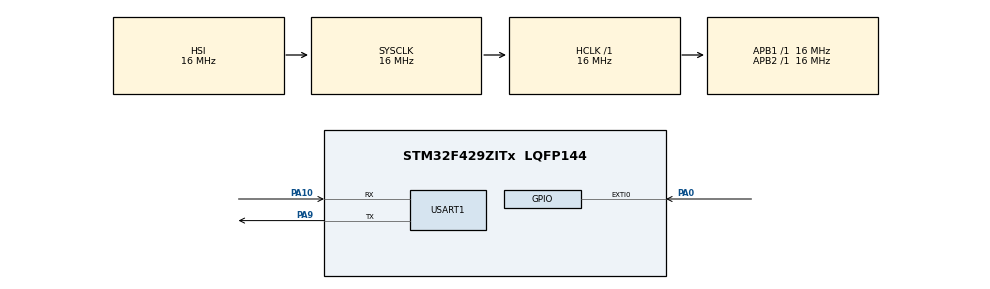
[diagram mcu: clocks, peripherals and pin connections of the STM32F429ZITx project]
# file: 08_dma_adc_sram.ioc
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ADC1.Channel-0\#ChannelRegularConversion=ADC_CHANNEL_TEMPSENSOR
ADC1.Channel-1\#ChannelRegularConversion=ADC_CHANNEL_TEMPSENSOR
ADC1.Channel-10\#ChannelRegularConversion=ADC_CHANNEL_TEMPSENSOR
ADC1.Channel-11\#ChannelRegularConversion=ADC_CHANNEL_TEMPSENSOR
ADC1.Channel-12\#ChannelRegularConversion=ADC_CHANNEL_TEMPSENSOR
ADC1.Channel-13\#ChannelRegularConversion=ADC_CHANNEL_TEMPSENSOR
ADC1.Channel-14\#ChannelRegularConversion=ADC_CHANNEL_TEMPSENSOR
ADC1.Channel-15\#ChannelRegularConversion=ADC_CHANNEL_TEMPSENSOR
ADC1.Channel-2\#ChannelRegularConversion=ADC_CHANNEL_TEMPSENSOR
ADC1.Channel-3\#ChannelRegularConversion=ADC_CHANNEL_TEMPSENSOR
ADC1.Channel-4\#ChannelRegularConversion=ADC_CHANNEL_TEMPSENSOR
ADC1.Channel-5\#ChannelRegularConversion=ADC_CHANNEL_TEMPSENSOR
ADC1.Channel-6\#ChannelRegularConversion=ADC_CHANNEL_TEMPSENSOR
ADC1.Channel-7\#ChannelRegularConversion=ADC_CHANNEL_TEMPSENSOR
ADC1.Channel-8\#ChannelRegularConversion=ADC_CHANNEL_TEMPSENSOR
ADC1.Channel-9\#ChannelRegularConversion=ADC_CHANNEL_TEMPSENSOR
ADC1.ClockPrescaler=ADC_CLOCK_SYNC_PCLK_DIV2
ADC1.ContinuousConvMode=ENABLE
ADC1.DMAContinuousRequests=DISABLE
ADC1.DataAlign=ADC_DATAALIGN_RIGHT
ADC1.DiscontinuousConvMode=DISABLE
ADC1.EOCSelection=ADC_EOC_SINGLE_CONV
ADC1.EnableAnalogWatchDog=false
ADC1.ExternalTrigConv=ADC_SOFTWARE_START
ADC1.ExternalTrigConvEdge=ADC_EXTERNALTRIGCONVEDGE_NONE
ADC1.InjNumberOfConversion=0
ADC1.NbrOfConversion=16
ADC1.NbrOfConversionFlag=1
ADC1.Rank-0\#ChannelRegularConversion=1
ADC1.Rank-1\#ChannelRegularConversion=2
ADC1.Rank-10\#ChannelRegularConversion=11
ADC1.Rank-11\#ChannelRegularConversion=12
ADC1.Rank-12\#ChannelRegularConversion=13
ADC1.Rank-13\#ChannelRegularConversion=14
ADC1.Rank-14\#ChannelRegularConversion=15
ADC1.Rank-15\#ChannelRegularConversion=16
ADC1.Rank-2\#ChannelRegularConversion=3
ADC1.Rank-3\#ChannelRegularConversion=4
ADC1.Rank-4\#ChannelRegularConversion=5
ADC1.Rank-5\#ChannelRegularConversion=6
ADC1.Rank-6\#ChannelRegularConversion=7
ADC1.Rank-7\#ChannelRegularConversion=8
ADC1.Rank-8\#ChannelRegularConversion=9
ADC1.Rank-9\#ChannelRegularConversion=10
ADC1.Resolution=ADC_RESOLUTION_12B
ADC1.SamplingTime-0\#ChannelRegularConversion=ADC_SAMPLETIME_3CYCLES
ADC1.SamplingTime-1\#ChannelRegularConversion=ADC_SAMPLETIME_3CYCLES
ADC1.SamplingTime-10\#ChannelRegularConversion=ADC_SAMPLETIME_3CYCLES
ADC1.SamplingTime-11\#ChannelRegularConversion=ADC_SAMPLETIME_3CYCLES
ADC1.SamplingTime-12\#ChannelRegularConversion=ADC_SAMPLETIME_3CYCLES
ADC1.SamplingTime-13\#ChannelRegularConversion=ADC_SAMPLETIME_3CYCLES
ADC1.SamplingTime-14\#ChannelRegularConversion=ADC_SAMPLETIME_3CYCLES
ADC1.SamplingTime-15\#ChannelRegularConversion=ADC_SAMPLETIME_3CYCLES
ADC1.SamplingTime-2\#ChannelRegularConversion=ADC_SAMPLETIME_3CYCLES
ADC1.SamplingTime-3\#ChannelRegularConversion=ADC_SAMPLETIME_3CYCLES
ADC1.SamplingTime-4\#ChannelRegularConversion=ADC_SAMPLETIME_3CYCLES
ADC1.SamplingTime-5\#ChannelRegularConversion=ADC_SAMPLETIME_3CYCLES
ADC1.SamplingTime-6\#ChannelRegularConversion=ADC_SAMPLETIME_3CYCLES
ADC1.SamplingTime-7\#ChannelRegularConversion=ADC_SAMPLETIME_3CYCLES
ADC1.SamplingTime-8\#ChannelRegularConversion=ADC_SAMPLETIME_3CYCLES
ADC1.SamplingTime-9\#ChannelRegularConversion=ADC_SAMPLETIME_3CYCLES
ADC1.ScanConvMode=ENABLE
ADC1.master=1
Dma.ADC1.0.Direction=DMA_PERIPH_TO_MEMORY
Dma.ADC1.0.FIFOMode=DMA_FIFOMODE_DISABLE
Dma.ADC1.0.Instance=DMA2_Stream0
Dma.ADC1.0.MemDataAlignment=DMA_MDATAALIGN_HALFWORD
Dma.ADC1.0.MemInc=DMA_MINC_ENABLE
Dma.ADC1.0.Mode=DMA_NORMAL
Dma.ADC1.0.PeriphDataAlignment=DMA_PDATAALIGN_HALFWORD
Dma.ADC1.0.PeriphInc=DMA_PINC_DISABLE
Dma.ADC1.0.Priority=DMA_PRIORITY_LOW
Dma.Request0=ADC1
Mcu.Family=STM32F4
Mcu.Name=STM32F429ZITx
Mcu.Package=LQFP144
NVIC.DMA2_Stream0_IRQn=true\:0\:0\:false\:false\:true\:false
NVIC.EXTI0_IRQn=true\:0\:0\:false\:false\:true\:true
NVIC.PriorityGroup=NVIC_PRIORITYGROUP_4
PA0/WKUP.Signal=GPXTI0
PA10.Mode=Asynchronous
PA10.Signal=USART1_RX
PA9.Mode=Asynchronous
PA9.Signal=USART1_TX
ProjectManager.HeapSize=0x200
ProjectManager.StackSize=0x400
ProjectManager.TargetToolchain=SW4STM32
RCC.AHBFreq_Value=16000000
RCC.APB1Freq_Value=16000000
RCC.APB2Freq_Value=16000000
RCC.CortexFreq_Value=16000000
RCC.HSE_VALUE=25000000
RCC.HSI_VALUE=16000000
RCC.LSE_VALUE=32768
RCC.SYSCLKFreq_VALUE=16000000
RCC.VCOOutputFreq_Value=192000000
USART1.VirtualMode=VM_ASYNC
VP_ADC1_TempSens_Input.Mode=IN-TempSens
board=custom

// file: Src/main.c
/**
  ******************************************************************************
  * @file           : main.c
  * @brief          : Main program body
  ******************************************************************************
  ** This notice applies to any and all portions of this file
  * that are not between comment pairs USER CODE BEGIN and
  * USER CODE END. Other portions of this file, whether
  * inserted by the user or by software development tools
  * are owned by their respective copyright owners.
  *
  * COPYRIGHT(c) 2020 STMicroelectronics
  *
  * Redistribution and use in source and binary forms, with or without modification,
  * are permitted provided that the following conditions are met:
  *   1. Redistributions of source code must retain the above copyright notice,
  *      this list of conditions and the following disclaimer.
  *   2. Redistributions in binary form must reproduce the above copyright notice,
  *      this list of conditions and the following disclaimer in the documentation
  *      and/or other materials provided with the distribution.
  *   3. Neither the name of STMicroelectronics nor the names of its contributors
  *      may be used to endorse or promote products derived from this software
  *      without specific prior written permission.
  *
  * THIS SOFTWARE IS PROVIDED BY THE COPYRIGHT HOLDERS AND CONTRIBUTORS "AS IS"
  * AND ANY EXPRESS OR IMPLIED WARRANTIES, INCLUDING, BUT NOT LIMITED TO, THE
  * IMPLIED WARRANTIES OF MERCHANTABILITY AND FITNESS FOR A PARTICULAR PURPOSE ARE
  * DISCLAIMED. IN NO EVENT SHALL THE COPYRIGHT HOLDER OR CONTRIBUTORS BE LIABLE
  * FOR ANY DIRECT, INDIRECT, INCIDENTAL, SPECIAL, EXEMPLARY, OR CONSEQUENTIAL
  * DAMAGES (INCLUDING, BUT NOT LIMITED TO, PROCUREMENT OF SUBSTITUTE GOODS OR
  * SERVICES; LOSS OF USE, DATA, OR PROFITS; OR BUSINESS INTERRUPTION) HOWEVER
  * CAUSED AND ON ANY THEORY OF LIABILITY, WHETHER IN CONTRACT, STRICT LIABILITY,
  * OR TORT (INCLUDING NEGLIGENCE OR OTHERWISE) ARISING IN ANY WAY OUT OF THE USE
  * OF THIS SOFTWARE, EVEN IF ADVISED OF THE POSSIBILITY OF SUCH DAMAGE.
  *
  ******************************************************************************
  */
#include "main.h"
#include "stm32f4xx_hal.h"

/* USER CODE BEGIN Includes */
#include <stdio.h>
#include <string.h>
#include <stdlib.h>
#include <stdint.h>
/* USER CODE END Includes */

ADC_HandleTypeDef hadc1;
DMA_HandleTypeDef hdma_adc1;

UART_HandleTypeDef huart1;

/* USER CODE BEGIN PV */
/* Private variables ---------------------------------------------------------*/

/* USER CODE END PV */

void SystemClock_Config(void);
static void MX_GPIO_Init(void);
static void MX_DMA_Init(void);
static void MX_ADC1_Init(void);
static void MX_USART1_UART_Init(void);

/* USER CODE BEGIN PFP */
/* Private function prototypes -----------------------------------------------*/

/* USER CODE END PFP */

/* USER CODE BEGIN 0 */
uint16_t temp_data[16];
volatile uint8_t dma_finish;
void HAL_GPIO_EXTI_Callback(uint16_t GPIO_Pin)
{
	HAL_ADC_Start_DMA(&hadc1, (uint32_t*)temp_data, 16);
}

void HAL_ADC_ConvCpltCallback(ADC_HandleTypeDef* hadc)
{
	dma_finish = 1;
}
/* USER CODE END 0 */

int main(void)
{

  /* MCU Configuration----------------------------------------------------------*/

  /* Reset of all peripherals, Initializes the Flash interface and the Systick. */
  HAL_Init();

  /* Configure the system clock */
  SystemClock_Config();

  /* Initialize all configured peripherals */
  MX_GPIO_Init();
  MX_DMA_Init();
  MX_ADC1_Init();
  MX_USART1_UART_Init();
  /* USER CODE BEGIN 2 */
  // HAL_ADC_Start_DMA(ADC_HandleTypeDef* hadc, uint32_t* pData, uint32_t Length);

  HAL_SuspendTick();
  /* USER CODE END 2 */

  /* Infinite loop */
  while (1)
  {

  /* USER CODE BEGIN 3 */
	  __disable_irq();
	  if(dma_finish) {
		  dma_finish = 0;
		  __enable_irq();

		  float temp_sum = 0;
		  for(int i=0; i<12; i++) {
			  temp_sum += temp_data[i];
		  }
		  temp_sum = temp_sum / 12.0;

		  float temp = (((temp_sum * (3.3/(2^12)-1)) - 0.76) / 2.5) + 25.0;

		  // print(temp);
	  }

	  __WFI();
  }
  /* USER CODE END 3 */

}

void SystemClock_Config(void)
{

  RCC_OscInitTypeDef RCC_OscInitStruct;
  RCC_ClkInitTypeDef RCC_ClkInitStruct;

    /**Configure the main internal regulator output voltage
    */
  __HAL_RCC_PWR_CLK_ENABLE();

  __HAL_PWR_VOLTAGESCALING_CONFIG(PWR_REGULATOR_VOLTAGE_SCALE3);

    /**Initializes the CPU, AHB and APB busses clocks
    */
  RCC_OscInitStruct.OscillatorType = RCC_OSCILLATORTYPE_HSI;
  RCC_OscInitStruct.HSIState = RCC_HSI_ON;
  RCC_OscInitStruct.HSICalibrationValue = 16;
  RCC_OscInitStruct.PLL.PLLState = RCC_PLL_NONE;
  if (HAL_RCC_OscConfig(&RCC_OscInitStruct) != HAL_OK)
  {
    _Error_Handler(__FILE__, __LINE__);
  }

    /**Initializes the CPU, AHB and APB busses clocks
    */
  RCC_ClkInitStruct.ClockType = RCC_CLOCKTYPE_HCLK|RCC_CLOCKTYPE_SYSCLK
                              |RCC_CLOCKTYPE_PCLK1|RCC_CLOCKTYPE_PCLK2;
  RCC_ClkInitStruct.SYSCLKSource = RCC_SYSCLKSOURCE_HSI;
  RCC_ClkInitStruct.AHBCLKDivider = RCC_SYSCLK_DIV1;
  RCC_ClkInitStruct.APB1CLKDivider = RCC_HCLK_DIV1;
  RCC_ClkInitStruct.APB2CLKDivider = RCC_HCLK_DIV1;

  if (HAL_RCC_ClockConfig(&RCC_ClkInitStruct, FLASH_LATENCY_0) != HAL_OK)
  {
    _Error_Handler(__FILE__, __LINE__);
  }

    /**Configure the Systick interrupt time
    */
  HAL_SYSTICK_Config(HAL_RCC_GetHCLKFreq()/1000);

    /**Configure the Systick
    */
  HAL_SYSTICK_CLKSourceConfig(SYSTICK_CLKSOURCE_HCLK);

  /* SysTick_IRQn interrupt configuration */
  HAL_NVIC_SetPriority(SysTick_IRQn, 0, 0);
}

/* ADC1 init function */
static void MX_ADC1_Init(void)
{

  ADC_ChannelConfTypeDef sConfig;

    /**Configure the global features of the ADC (Clock, Resolution, Data Alignment and number of conversion)
    */
  hadc1.Instance = ADC1;
  hadc1.Init.ClockPrescaler = ADC_CLOCK_SYNC_PCLK_DIV2;
  hadc1.Init.Resolution = ADC_RESOLUTION_12B;
  hadc1.Init.ScanConvMode = ENABLE;
  hadc1.Init.ContinuousConvMode = ENABLE;
  hadc1.Init.DiscontinuousConvMode = DISABLE;
  hadc1.Init.ExternalTrigConvEdge = ADC_EXTERNALTRIGCONVEDGE_NONE;
  hadc1.Init.ExternalTrigConv = ADC_SOFTWARE_START;
  hadc1.Init.DataAlign = ADC_DATAALIGN_RIGHT;
  hadc1.Init.NbrOfConversion = 16;
  hadc1.Init.DMAContinuousRequests = DISABLE;
  hadc1.Init.EOCSelection = ADC_EOC_SINGLE_CONV;
  if (HAL_ADC_Init(&hadc1) != HAL_OK)
  {
    _Error_Handler(__FILE__, __LINE__);
  }

    /**Configure for the selected ADC regular channel its corresponding rank in the sequencer and its sample time.
    */
  sConfig.Channel = ADC_CHANNEL_TEMPSENSOR;
  sConfig.Rank = 1;
  sConfig.SamplingTime = ADC_SAMPLETIME_3CYCLES;
  if (HAL_ADC_ConfigChannel(&hadc1, &sConfig) != HAL_OK)
  {
    _Error_Handler(__FILE__, __LINE__);
  }

    /**Configure for the selected ADC regular channel its corresponding rank in the sequencer and its sample time.
    */
  sConfig.Rank = 2;
  if (HAL_ADC_ConfigChannel(&hadc1, &sConfig) != HAL_OK)
  {
    _Error_Handler(__FILE__, __LINE__);
  }

    /**Configure for the selected ADC regular channel its corresponding rank in the sequencer and its sample time.
    */
  sConfig.Rank = 3;
  if (HAL_ADC_ConfigChannel(&hadc1, &sConfig) != HAL_OK)
  {
    _Error_Handler(__FILE__, __LINE__);
  }

    /**Configure for the selected ADC regular channel its corresponding rank in the sequencer and its sample time.
    */
  sConfig.Rank = 4;
  if (HAL_ADC_ConfigChannel(&hadc1, &sConfig) != HAL_OK)
  {
    _Error_Handler(__FILE__, __LINE__);
  }

    /**Configure for the selected ADC regular channel its corresponding rank in the sequencer and its sample time.
    */
  sConfig.Rank = 5;
  if (HAL_ADC_ConfigChannel(&hadc1, &sConfig) != HAL_OK)
  {
    _Error_Handler(__FILE__, __LINE__);
  }

    /**Configure for the selected ADC regular channel its corresponding rank in the sequencer and its sample time.
    */
  sConfig.Rank = 6;
  if (HAL_ADC_ConfigChannel(&hadc1, &sConfig) != HAL_OK)
  {
    _Error_Handler(__FILE__, __LINE__);
  }

    /**Configure for the selected ADC regular channel its corresponding rank in the sequencer and its sample time.
    */
  sConfig.Rank = 7;
  if (HAL_ADC_ConfigChannel(&hadc1, &sConfig) != HAL_OK)
  {
    _Error_Handler(__FILE__, __LINE__);
  }

    /**Configure for the selected ADC regular channel its corresponding rank in the sequencer and its sample time.
    */
  sConfig.Rank = 8;
  if (HAL_ADC_ConfigChannel(&hadc1, &sConfig) != HAL_OK)
  {
    _Error_Handler(__FILE__, __LINE__);
  }

    /**Configure for the selected ADC regular channel its corresponding rank in the sequencer and its sample time.
    */
  sConfig.Rank = 9;
  if (HAL_ADC_ConfigChannel(&hadc1, &sConfig) != HAL_OK)
  {
    _Error_Handler(__FILE__, __LINE__);
  }

    /**Configure for the selected ADC regular channel its corresponding rank in the sequencer and its sample time.
    */
  sConfig.Rank = 10;
  if (HAL_ADC_ConfigChannel(&hadc1, &sConfig) != HAL_OK)
  {
    _Error_Handler(__FILE__, __LINE__);
  }

    /**Configure for the selected ADC regular channel its corresponding rank in the sequencer and its sample time.
    */
  sConfig.Rank = 11;
  if (HAL_ADC_ConfigChannel(&hadc1, &sConfig) != HAL_OK)
  {
    _Error_Handler(__FILE__, __LINE__);
  }

    /**Configure for the selected ADC regular channel its corresponding rank in the sequencer and its sample time.
    */
  sConfig.Rank = 12;
  if (HAL_ADC_ConfigChannel(&hadc1, &sConfig) != HAL_OK)
  {
    _Error_Handler(__FILE__, __LINE__);
  }

    /**Configure for the selected ADC regular channel its corresponding rank in the sequencer and its sample time.
    */
  sConfig.Rank = 13;
  if (HAL_ADC_ConfigChannel(&hadc1, &sConfig) != HAL_OK)
  {
    _Error_Handler(__FILE__, __LINE__);
  }

    /**Configure for the selected ADC regular channel its corresponding rank in the sequencer and its sample time.
    */
  sConfig.Rank = 14;
  if (HAL_ADC_ConfigChannel(&hadc1, &sConfig) != HAL_OK)
  {
    _Error_Handler(__FILE__, __LINE__);
  }

    /**Configure for the selected ADC regular channel its corresponding rank in the sequencer and its sample time.
    */
  sConfig.Rank = 15;
  if (HAL_ADC_ConfigChannel(&hadc1, &sConfig) != HAL_OK)
  {
    _Error_Handler(__FILE__, __LINE__);
  }

    /**Configure for the selected ADC regular channel its corresponding rank in the sequencer and its sample time.
    */
  sConfig.Rank = 16;
  if (HAL_ADC_ConfigChannel(&hadc1, &sConfig) != HAL_OK)
  {
    _Error_Handler(__FILE__, __LINE__);
  }

}

/* USART1 init function */
static void MX_USART1_UART_Init(void)
{

  huart1.Instance = USART1;
  huart1.Init.BaudRate = 115200;
  huart1.Init.WordLength = UART_WORDLENGTH_8B;
  huart1.Init.StopBits = UART_STOPBITS_1;
  huart1.Init.Parity = UART_PARITY_NONE;
  huart1.Init.Mode = UART_MODE_TX_RX;
  huart1.Init.HwFlowCtl = UART_HWCONTROL_NONE;
  huart1.Init.OverSampling = UART_OVERSAMPLING_16;
  if (HAL_UART_Init(&huart1) != HAL_OK)
  {
    _Error_Handler(__FILE__, __LINE__);
  }

}

static void MX_DMA_Init(void)
{
  /* DMA controller clock enable */
  __HAL_RCC_DMA2_CLK_ENABLE();

  /* DMA interrupt init */
  /* DMA2_Stream0_IRQn interrupt configuration */
  HAL_NVIC_SetPriority(DMA2_Stream0_IRQn, 0, 0);
  HAL_NVIC_EnableIRQ(DMA2_Stream0_IRQn);

}

/** Configure pins as
        * Analog
        * Input
        * Output
        * EVENT_OUT
        * EXTI
*/
static void MX_GPIO_Init(void)
{

  GPIO_InitTypeDef GPIO_InitStruct;

  /* GPIO Ports Clock Enable */
  __HAL_RCC_GPIOA_CLK_ENABLE();

  /*Configure GPIO pin : PA0 */
  GPIO_InitStruct.Pin = GPIO_PIN_0;
  GPIO_InitStruct.Mode = GPIO_MODE_IT_RISING;
  GPIO_InitStruct.Pull = GPIO_NOPULL;
  HAL_GPIO_Init(GPIOA, &GPIO_InitStruct);

  /* EXTI interrupt init*/
  HAL_NVIC_SetPriority(EXTI0_IRQn, 0, 0);
  HAL_NVIC_EnableIRQ(EXTI0_IRQn);

}

void _Error_Handler(char *file, int line)
{
  while(1)
  {
  }
}

/************************ (C) COPYRIGHT STMicroelectronics *****END OF FILE****/
